# STM32N655 register map
File version: 1.0
CPU: CM55 r0p1, little endian, no MPU, FPU, vendor SysTick, 8 interrupt priority bits
Registers are 32-bit, read-write, reset 0x0 unless marked. A register's access mark holds for its fields unless they carry their own. Offsets are from the block's base; [hi:lo] are bit positions.

## TIM6 — Basic timers
Base 0x40001000
Same registers: TIM6_S 0x50001000
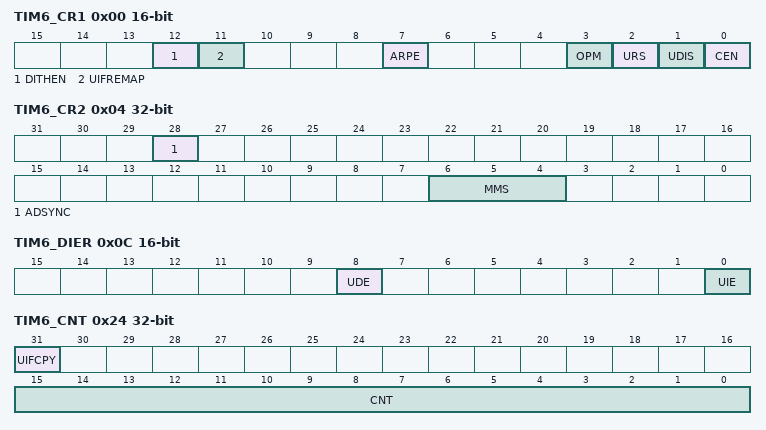
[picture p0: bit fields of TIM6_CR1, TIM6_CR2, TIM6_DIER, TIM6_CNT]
0x00 TIM6_CR1 16-bit — TIM6 control register 1
  [12] DITHEN — Dithering enable
    0=Dithering disabled; 1=Dithering enabled
  [11] UIFREMAP — UIF status bit remapping
    0=No remapping. UIF status bit is not copied to TIMx_CNT register bit 31.; 1=Remapping enabled. UIF status bit is copied to TIMx_CNT register bit 31.
  [7] ARPE — Auto-reload preload enable
    0=TIMx_ARR register is not buffered; 1=TIMx_ARR register is buffered
  [3] OPM — One-pulse mode
    0=Counter is not stopped at update event; 1=Counter stops counting at the next update event (clearing the CEN bit)
  [2] URS — Update request source
    0=Any of the following events generates an update interrupt or DMA request if enabled. These events can be:; 1=Only counter overflow/underflow generates an update interrupt or DMA request if enabled
  [1] UDIS — Update disable
    0=UEV enabled. The Update (UEV) event is generated by one of the following events:; 1=UEV disabled. The Update event is not generated, shadow registers keep their value (ARR, PSC). However the counter and the prescaler are reinitialized if the UG bit is set or if a hardware reset is received from the slave mode controller.
  [0] CEN — Counter enable
    0=Counter disabled; 1=Counter enabled
0x04 TIM6_CR2 — TIM6 control register 2
  [28] ADSYNC — ADC synchronization
    0=The timer operates independently from the ADC; 1=The timer operation is synchronized with the ADC clock to provide jitter-free sampling point. This mode can be enabled only with specific ADC / timer clock relationship. Refer to Section 48.3.8 for requirements.
  [6:4] MMS — Master mode selection
    0=Reset - the UG bit from the TIMx_EGR register is used as a trigger output (tim_trgo); 1=Enable - the Counter enable signal, tim_cnt_en, is used as a trigger output (tim_trgo). It is useful to start several timers at the same time or to control a window in which a slave timer is enabled. The Counter Enable signal is generated when the CEN control bit is written.; 2=Update - The update event is selected as a trigger output (tim_trgo). For instance a master timer can then be used as a prescaler for a slave timer.
0x0C TIM6_DIER 16-bit — TIM6 DMA/Interrupt enable register
  [8] UDE — Update DMA request enable
    0=Update DMA request disabled; 1=Update DMA request enabled
  [0] UIE — Update interrupt enable
    0=Update interrupt disabled; 1=Update interrupt enabled
0x10 TIM6_SR 16-bit — TIM6 status register
  [0] UIF — Update interrupt flag
    0=No update occurred; 1=Update interrupt pending. This bit is set by hardware when the registers are updated:
0x14 TIM6_EGR 16-bit wo — TIM6 event generation register
  [0] UG — Update generation
    0=No action; 1=Re-initializes the timer counter and generates an update of the registers. Note that the prescaler counter is cleared too (but the prescaler ratio is not affected).
0x24 TIM6_CNT access per field — TIM6 counter
  [31] UIFCPY ro — UIF copy
  [15:0] CNT rw — Counter value
0x28 TIM6_PSC 16-bit — TIM6 prescaler
  [15:0] PSC — Prescaler value
0x2C TIM6_ARR reset 0xFFFF — TIM6 auto-reload register
  [19:0] ARR — Auto-reload value

## TIM7 — Basic timers
Base 0x40001400
Same registers: TIM7_S 0x50001400
Registers as TIM6 (with TIM6 read as TIM7).

## TIM18 — Basic timers
Base 0x42003C00
Same registers: TIM18_S 0x52003C00
Registers as TIM6 (with TIM6 read as TIM18).

## VREFBUF — Voltage reference buffer
Base 0x46003C00
Same registers: VREFBUF_S 0x56003C00
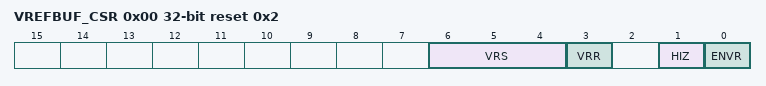
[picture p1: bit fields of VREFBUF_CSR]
0x00 VREFBUF_CSR access per field reset 0x2 — VREFBUF control and status register
  [6:4] VRS rw — Voltage reference scale
  [3] VRR ro — Voltage reference buffer ready
    0=the voltage reference buffer output is not ready; 1=the voltage reference buffer output reached the requested level
  [1] HIZ rw — High impedance mode
    0=Vless thansub>REF+less than/sub> pin is internally connected to the voltage reference buffer output; 1=Vless thansub>REF+less than/sub> pin is high impedance
  [0] ENVR rw — Voltage reference buffer mode enable
    0=Internal voltage reference mode disable (external voltage reference mode); 1=Internal voltage reference mode (reference buffer enable or hold mode) enable
0x04 VREFBUF_CCR (reset mask 0xFFFFFF00) — VREFBUF calibration control register
  [5:0] TRIM — Trimming code

## WWDG — System window watchdog
Base 0x40002C00
Same registers: WWDG_S 0x50002C00
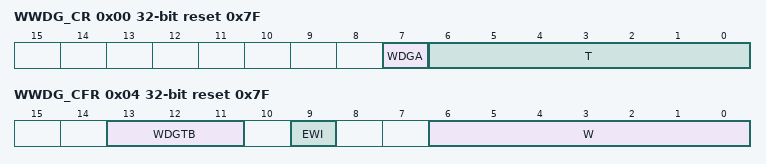
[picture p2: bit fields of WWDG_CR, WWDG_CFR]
0x00 WWDG_CR reset 0x7F — WWDG control register
  [7] WDGA — Activation bit
    0=Watchdog disabled; 1=Watchdog enabled
  [6:0] T — 7-bit counter (MSB to LSB)
0x04 WWDG_CFR reset 0x7F — WWDG configuration register
  [13:11] WDGTB — Timer base
    0=CK counter clock (PCLK div 4096) div 1; 1=CK counter clock (PCLK div 4096) div 2; 2=CK counter clock (PCLK div 4096) div 4; 3=CK counter clock (PCLK div 4096) div 8; 4=CK counter clock (PCLK div 4096) div 16; 5=CK counter clock (PCLK div 4096) div 32; 6=CK counter clock (PCLK div 4096) div 64; 7=CK counter clock (PCLK div 4096) div 128
  [9] EWI — Early wakeup interrupt
  [6:0] W — 7-bit window value
0x08 WWDG_SR — WWDG status register
  [0] EWIF — Early wakeup interrupt flag

## XSPIM — XSPI I/O manager
Base 0x4802B400
Same registers: XSPIM_S 0x5802B400
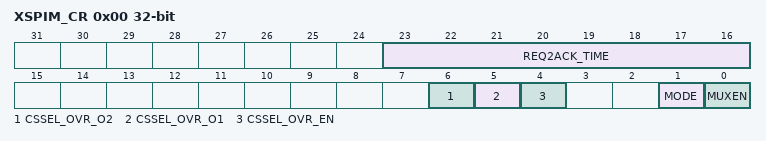
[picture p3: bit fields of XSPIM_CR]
0x00 XSPIM_CR — XSPIM control register
  [23:16] REQ2ACK_TIME — REQ to ACK time
  [6] CSSEL_OVR_O2 — Chip select selector override setting for XSPI2
    0=XSPI2 can only use NCS1 (accesses using NCS2 are ignored); 1=XSPI2 can only use NCS2 (accesses using NCS1 are ignored)
  [5] CSSEL_OVR_O1 — Chip select selector override setting for XSPI1
    0=XSPI1 can only use NCS1 (accesses using NCS2 are ignored); 1=XSPI1 can only use NCS2 (accesses using NCS1 are ignored)
  [4] CSSEL_OVR_EN — Chip select selector override enable
    0=CSSEL_OVR_O1 and CSSEL_OVR_O2 bit values are ignored, the chip select signals from OCTOSPIs or XSPIs are transmitted unconditionally; 1=CSSEL_OVR_O1 and CSSEL_OVR_O2 bit values are taken into account
  [1] MODE — XSPI multiplexing mode
    0=if MUXEN = 0 direct mode, if MUXEN = 1 arbitration mode to output Port 1; 1=if MUXEN = 0 swapped mode, if MUXEN = 1 arbitration mode to output Port 2
  [0] MUXEN — Multiplexed mode enable
    0=No multiplexing, hence no arbitration; 1=XSPI1 and XSPI2 are multiplexed over the same bus
